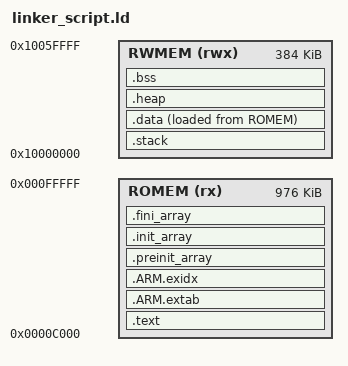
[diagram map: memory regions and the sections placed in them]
/******************************************************************************
 *
 * hello_world.ld - Linker script for applications using startup_gnu.c
 *
 *****************************************************************************/
ENTRY(Reset_Handler)

MEMORY
{
    ROMEM (rx) : ORIGIN = 0x0000C000, LENGTH = 976K
    RWMEM (rwx) : ORIGIN = 0x10000000, LENGTH = 384K
}

SECTIONS
{
    .text :
    {
        . = ALIGN(4);
        KEEP(*(.isr_vector))
        KEEP(*(.patch))
        *(.text)
        *(.text*)
        *(.rodata)
        *(.rodata*)
        . = ALIGN(4);
        _etext = .;
    } > ROMEM


    .ARM.extab :
    {
        *(.ARM.extab* .gnu.linkonce.armextab.*)
    } > ROMEM

    __exidx_start = .;
    .ARM.exidx :
    {
        *(.ARM.exidx* .gnu.linkonce.armexidx.*)
    } > ROMEM
    __exidx_end = .;

    .preinit_array :
    {
        PROVIDE_HIDDEN (__preinit_array_start = .);
        KEEP (*(.preinit_array*))
        PROVIDE_HIDDEN (__preinit_array_end = .);
    } > ROMEM

    .init_array :
    {
        PROVIDE_HIDDEN (__init_array_start = .);
        KEEP (*(SORT(.init_array.*)))
        KEEP (*(.init_array*))
        PROVIDE_HIDDEN (__init_array_end = .);
    } > ROMEM

    .fini_array :
    {
        PROVIDE_HIDDEN (__fini_array_start = .);
        KEEP (*(SORT(.fini_array.*)))
        KEEP (*(.fini_array*))
        PROVIDE_HIDDEN (__fini_array_end = .);
    } > ROMEM

    /* User stack section initialized by startup code. */
    .stack (NOLOAD):
    {
        . = ALIGN(8);
        *(.stack)
        *(.stack*)
        . = ALIGN(8);
    } > RWMEM

    .data :
    {
        . = ALIGN(4);
        _sdata = .;
        *(.data)
        *(.data*)
        . = ALIGN(4);
        _edata = .;
    } > RWMEM AT>ROMEM

    /* used by startup to initialize data */
    _init_data = LOADADDR(.data);

    .heap : {
        __heap_start__ = .;
        end = __heap_start__;
        _end = end;
        __end = end;
        KEEP(*(.heap))
        __heap_end__ = .;
        __HeapLimit = __heap_end__;
    } > RWMEM

    .bss :
    {
        . = ALIGN(4);
        _sbss = .;
        *(.bss)
        *(.bss*)
        *(COMMON)
        . = ALIGN(4);
        _ebss = .;
    } > RWMEM

    .ARM.attributes 0 : { *(.ARM.attributes) }
}
